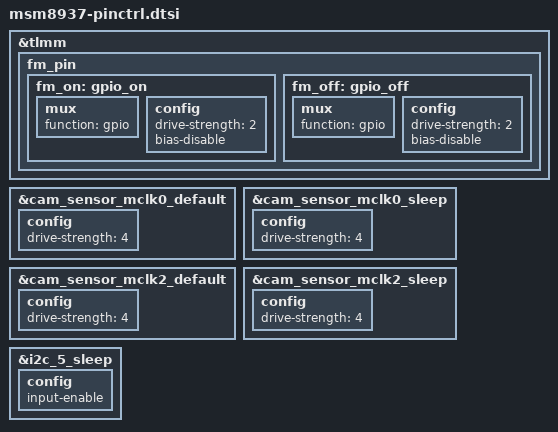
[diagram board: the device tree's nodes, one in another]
&tlmm {
		fm_pin {
			fm_on: gpio_on {
				mux {
					function = "gpio";
				};

				config {
					drive-strength = <2>;
					bias-disable;
				};
			};

			fm_off: gpio_off {
				mux {
					function = "gpio";
				};

				config {
					drive-strength = <2>;
					bias-disable;
				};
			};
		};
};

&cam_sensor_mclk0_default {
	config {
		drive-strength = <4>;
	};
};

&cam_sensor_mclk0_sleep {
	config {
		drive-strength = <4>;
	};
};

&cam_sensor_mclk2_default {
	config {
		drive-strength = <4>;
	};
};

&cam_sensor_mclk2_sleep {
	config {
		drive-strength = <4>;
	};
};

&i2c_5_sleep {
	config {
		input-enable;
	};
};
